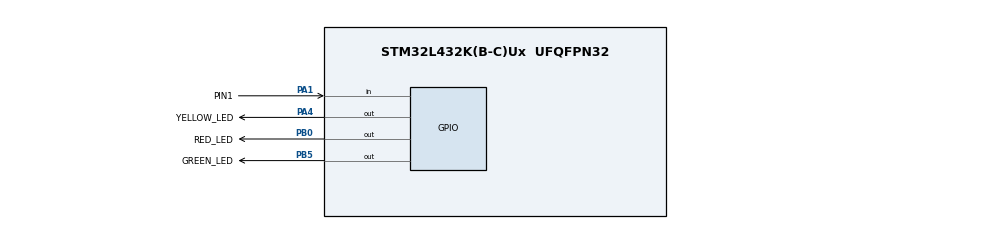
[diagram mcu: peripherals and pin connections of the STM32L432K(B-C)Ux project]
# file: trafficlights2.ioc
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Mcu.Family=STM32L4
Mcu.Name=STM32L432K(B-C)Ux
Mcu.Package=UFQFPN32
NVIC.PriorityGroup=NVIC_PRIORITYGROUP_4
PA1.GPIO_Label=PIN1
PA1.Signal=GPIO_Input
PA4.GPIO_Label=YELLOW_LED
PA4.Signal=GPIO_Output
PB0.GPIO_Label=RED_LED
PB0.Signal=GPIO_Output
PB5.GPIO_Label=GREEN_LED
PB5.Signal=GPIO_Output
ProjectManager.HeapSize=0x200
ProjectManager.StackSize=0x400
ProjectManager.TargetToolchain=STM32CubeIDE
RCC.HSE_VALUE=8000000
RCC.HSI48_VALUE=48000000
RCC.HSI_VALUE=16000000
RCC.LSE_VALUE=32768
RCC.MSI_VALUE=4000000
RCC.VCOOutputFreq_Value=32000000
board=custom

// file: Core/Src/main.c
/* USER CODE BEGIN Header */
/**
  ******************************************************************************
  * @file           : main.c
  * @brief          : Main program body
  ******************************************************************************
  * @attention
  *
  * <h2><center>&copy; Copyright (c) 2021 STMicroelectronics.
  * All rights reserved.</center></h2>
  *
  * This software component is licensed by ST under BSD 3-Clause license,
  * the "License"; You may not use this file except in compliance with the
  * License. You may obtain a copy of the License at:
  *                        opensource.org/licenses/BSD-3-Clause
  *
  ******************************************************************************
  */
/* USER CODE END Header */

#include "main.h"

#include<stdbool.h>

/* USER CODE BEGIN PFP */

void SystemClock_Config(void);
static void MX_GPIO_Init(void);

/* USER CODE END PFP */

uint8_t button=0;
bool state = false;

bool Button_pressed()
{

	if( HAL_GPIO_ReadPin(PIN1_GPIO_Port, PIN1_Pin)==1 &&state==false)
	{
		button ++;
		state= true;
	}
	else if( HAL_GPIO_ReadPin(PIN1_GPIO_Port, PIN1_Pin) == 0 && state == true)
		{
			state = false;
		}

		if(button%2 == 0)
			return true;
		else
			return false;
}

static void red(int state)
{
	HAL_GPIO_WritePin(RED_LED_GPIO_Port, RED_LED_Pin, state);

}
static void yellow(int state)
{
	HAL_GPIO_WritePin(YELLOW_LED_GPIO_Port, YELLOW_LED_Pin, state);

}

static void green(int state)
{
	HAL_GPIO_WritePin(GREEN_LED_GPIO_Port, GREEN_LED_Pin, state);

}

static void red_yellow(int state)
{
	HAL_GPIO_WritePin(YELLOW_LED_GPIO_Port, YELLOW_LED_Pin, state);
	HAL_GPIO_WritePin(RED_LED_GPIO_Port, RED_LED_Pin, state);

}

static int wait(int time)
{
	for (int i=0; i < time;i++)
	{
  	 	  HAL_Delay(1);

  	 	if(!Button_pressed())
  	 						{
  	 									HAL_Delay(50);
  	 									return 1;
  	 								}
	}
	return 0;
}
static void	blinking() {

    while(!Button_pressed())   // Blinking if button not pressed
     {
    	red(0);
    	green(0);

    	yellow(1);
    	HAL_Delay(100);
    	if(Button_pressed())break;
    	yellow(0);
    	HAL_Delay(100);
    	if(Button_pressed())break; //

     }

  }

static void Ampel_On()
{

				while(1)

			{
					yellow(0);
					red(1);
					if (wait(2000)) break;
					red(0);
				  	red_yellow(1);

					if(wait(1000)) break;
					red_yellow(0);
					green(1);
					if (wait(2000)) break;
					green(0);
					yellow(1);
					if (wait(1000)) break;

			}
}

int main(void)
{

  /* MCU Configuration--------------------------------------------------------*/

  /* Reset of all peripherals, Initializes the Flash interface and the Systick. */
  HAL_Init();

  /* Configure the system clock */
  SystemClock_Config();

  /* Initialize all configured peripherals */
  MX_GPIO_Init();

  /* Infinite loop */
  /* USER CODE BEGIN WHILE */

  while (1)
  {
	  blinking();
	  Ampel_On();

  }

  /* USER CODE END 3 */
}

void SystemClock_Config(void)
{
  RCC_OscInitTypeDef RCC_OscInitStruct = {0};
  RCC_ClkInitTypeDef RCC_ClkInitStruct = {0};

  /** Initializes the CPU, AHB and APB busses clocks
  */
  RCC_OscInitStruct.OscillatorType = RCC_OSCILLATORTYPE_MSI;
  RCC_OscInitStruct.MSIState = RCC_MSI_ON;
  RCC_OscInitStruct.MSICalibrationValue = 0;
  RCC_OscInitStruct.MSIClockRange = RCC_MSIRANGE_6;
  RCC_OscInitStruct.PLL.PLLState = RCC_PLL_NONE;
  if (HAL_RCC_OscConfig(&RCC_OscInitStruct) != HAL_OK)
  {
    Error_Handler();
  }
  /** Initializes the CPU, AHB and APB busses clocks
  */
  RCC_ClkInitStruct.ClockType = RCC_CLOCKTYPE_HCLK|RCC_CLOCKTYPE_SYSCLK
                              |RCC_CLOCKTYPE_PCLK1|RCC_CLOCKTYPE_PCLK2;
  RCC_ClkInitStruct.SYSCLKSource = RCC_SYSCLKSOURCE_MSI;
  RCC_ClkInitStruct.AHBCLKDivider = RCC_SYSCLK_DIV1;
  RCC_ClkInitStruct.APB1CLKDivider = RCC_HCLK_DIV1;
  RCC_ClkInitStruct.APB2CLKDivider = RCC_HCLK_DIV1;

  if (HAL_RCC_ClockConfig(&RCC_ClkInitStruct, FLASH_LATENCY_0) != HAL_OK)
  {
    Error_Handler();
  }
  /** Configure the main internal regulator output voltage
  */
  if (HAL_PWREx_ControlVoltageScaling(PWR_REGULATOR_VOLTAGE_SCALE1) != HAL_OK)
  {
    Error_Handler();
  }
}

static void MX_GPIO_Init(void)
{
  GPIO_InitTypeDef GPIO_InitStruct = {0};

  /* GPIO Ports Clock Enable */
  __HAL_RCC_GPIOA_CLK_ENABLE();
  __HAL_RCC_GPIOB_CLK_ENABLE();

  /*Configure GPIO pin Output Level */
  HAL_GPIO_WritePin(YELLOW_LED_GPIO_Port, YELLOW_LED_Pin, GPIO_PIN_RESET);

  /*Configure GPIO pin Output Level */
  HAL_GPIO_WritePin(GPIOB, RED_LED_Pin|GREEN_LED_Pin|YELLOW_LED_Pin, GPIO_PIN_RESET);

  /*Configure GPIO pin : PIN1_Pin */
  GPIO_InitStruct.Pin = PIN1_Pin;
  GPIO_InitStruct.Mode = GPIO_MODE_INPUT;
  GPIO_InitStruct.Pull = GPIO_NOPULL;
  HAL_GPIO_Init(PIN1_GPIO_Port, &GPIO_InitStruct);

  /*Configure GPIO pin : YELLOW_LED_Pin */
  GPIO_InitStruct.Pin = YELLOW_LED_Pin;
  GPIO_InitStruct.Mode = GPIO_MODE_OUTPUT_PP;
  GPIO_InitStruct.Pull = GPIO_NOPULL;
  GPIO_InitStruct.Speed = GPIO_SPEED_FREQ_LOW;
  HAL_GPIO_Init(YELLOW_LED_GPIO_Port, &GPIO_InitStruct);

  /*Configure GPIO pins : RED_LED_Pin GREEN_LED_Pin */
  GPIO_InitStruct.Pin = RED_LED_Pin|GREEN_LED_Pin;
  GPIO_InitStruct.Mode = GPIO_MODE_OUTPUT_PP;
  GPIO_InitStruct.Pull = GPIO_NOPULL;
  GPIO_InitStruct.Speed = GPIO_SPEED_FREQ_LOW;
  HAL_GPIO_Init(GPIOB, &GPIO_InitStruct);

}

void Error_Handler(void)
{
}

/**/

/************************ (C) COPYRIGHT STMicroelectronics *****END OF FILE****/
